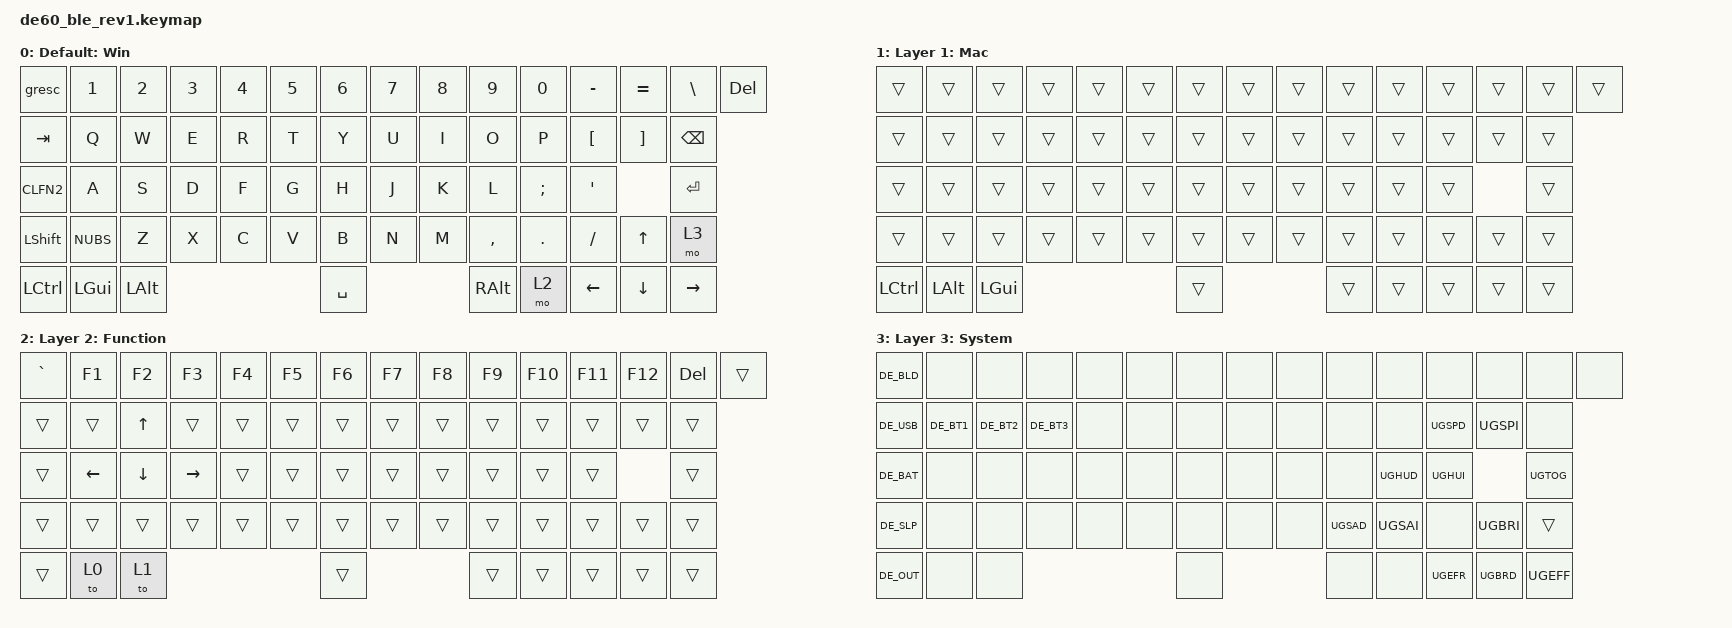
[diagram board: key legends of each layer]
/*
 * Copyright (c) 2026 DEKB
 * SPDX-License-Identifier: MIT
 */

#include "common.keymap"

/ {
    keymap {
        compatible = "zmk,keymap";

        base {
            label = "Default: Win";
            bindings = <
&gresc    &kp N1    &kp N2    &kp N3    &kp N4    &kp N5    &kp N6    &kp N7    &kp N8    &kp N9    &kp N0    &kp MINUS &kp EQUAL &kp BSLH  &kp DEL
&kp TAB   &kp Q     &kp W     &kp E     &kp R     &kp T     &kp Y     &kp U     &kp I     &kp O     &kp P     &kp LBKT  &kp RBKT  &kp BSPC
CLFN2    &kp A     &kp S     &kp D     &kp F     &kp G     &kp H     &kp J     &kp K     &kp L     &kp SEMI  &kp SQT             &kp ENTER
&kp LSHFT &kp NUBS  &kp Z     &kp X     &kp C     &kp V     &kp B     &kp N     &kp M     &kp COMMA &kp DOT   &kp FSLH  &kp UP    &mo 3
&kp LCTRL &kp LGUI  &kp LALT                                &kp SPACE                     &kp RALT  &mo 2     &kp LEFT  &kp DOWN  &kp RIGHT
            >;
        };

        layer_1 {
            label = "Layer 1: Mac";
            bindings = <
&trans    &trans    &trans    &trans    &trans    &trans    &trans    &trans    &trans    &trans    &trans    &trans    &trans    &trans    &trans
&trans    &trans    &trans    &trans    &trans    &trans    &trans    &trans    &trans    &trans    &trans    &trans    &trans    &trans
&trans    &trans    &trans    &trans    &trans    &trans    &trans    &trans    &trans    &trans    &trans    &trans              &trans
&trans    &trans    &trans    &trans    &trans    &trans    &trans    &trans    &trans    &trans    &trans    &trans    &trans    &trans
&kp LCTRL &kp LALT  &kp LGUI                                &trans                        &trans    &trans    &trans    &trans    &trans
            >;
        };

        layer_2 {
            label = "Layer 2: Function";
            bindings = <
&kp GRAVE &kp F1    &kp F2    &kp F3    &kp F4    &kp F5    &kp F6    &kp F7    &kp F8    &kp F9    &kp F10   &kp F11   &kp F12   &kp DEL    &trans
&trans    &trans    &kp UP    &trans    &trans    &trans    &trans    &trans    &trans    &trans    &trans    &trans    &trans    &trans
&trans    &kp LEFT  &kp DOWN  &kp RIGHT &trans    &trans    &trans    &trans    &trans    &trans    &trans    &trans              &trans
&trans    &trans    &trans    &trans    &trans    &trans    &trans    &trans    &trans    &trans    &trans    &trans    &trans    &trans
&trans    &to 0     &to 1                                   &trans                        &trans    &trans    &trans    &trans    &trans
            >;
        };

        layer_3 {
            label = "Layer 3: System";
            bindings = <
&DE_BLD   &none     &none     &none     &none     &none     &none     &none     &none     &none     &none     &none     &none     &none     &none
&DE_USB   &DE_BT1   &DE_BT2   &DE_BT3   &none     &none     &none     &none     &none     &none     &none     &UGSPD    &UGSPI    &none
&DE_BAT   &none     &none     &none     &none     &none     &none     &none     &none     &none     &UGHUD    &UGHUI              &UGTOG
&DE_SLP   &none     &none     &none     &none     &none     &none     &none     &none     &UGSAD    &UGSAI    &none     &UGBRI    &trans
&DE_OUT   &none     &none                                   &none                         &none     &none     &UGEFR    &UGBRD    &UGEFF
            >;
        };

        layer_4 { status = "reserved"; };
        layer_5 { status = "reserved"; };
        layer_6 { status = "reserved"; };
        layer_7 { status = "reserved"; };
    };
};
